# STM32C551xx register map
File version: 1.0
Registers are 32-bit, read-write, reset 0x0 unless marked. A register's access mark holds for its fields unless they carry their own. Offsets are from the block's base; [hi:lo] are bit positions.

## SPI2 — Serial peripheral interface (SPI)
Base 0x40003800
Same registers: SPI3 0x40003C00, SPI1 0x40013000
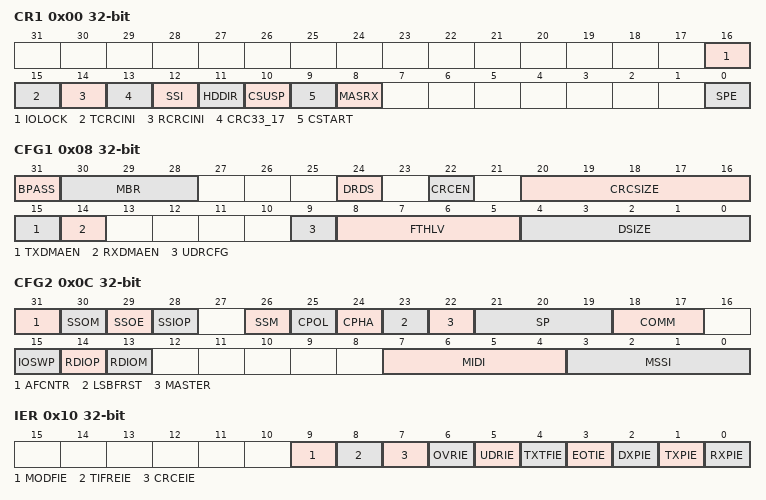
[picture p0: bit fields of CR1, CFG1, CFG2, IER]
0x00 CR1 — SPI/I2S Control register 1
  [16] IOLOCK — Locking the AF configuration of associated IOs
  [15] TCRCINI — CRC init pattern control for transmitter
  [14] RCRCINI — CRC init pattern control for receiver
  [13] CRC33_17 — 32-bit CRC polynomial configuration
  [12] SSI — Internal SS signal input level
  [11] HDDIR — Rx/Tx direction at Half-duplex mode
  [10] CSUSP — Master SUSPend request
  [9] CSTART — Master transfer start
  [8] MASRX — Master automatic SUSP in Receive mode
  [0] SPE — Serial Peripheral Enable
0x04 CR2 — SPI Control register 2
  [15:0] TSIZE — Number of data at current transfer
0x08 CFG1 — SPI Configuration register 1
  [31] BPASS — Bypass of the prescaler
  [30:28] MBR — Master baud rate
  [24] DRDS — Delay Read Data Sampling
  [22] CRCEN — Hardware CRC computation enable
  [20:16] CRCSIZE — CRCSIZE [4:0]: Length of CRC frame
  [15] TXDMAEN — Tx DMA stream enable
  [14] RXDMAEN — Rx DMA stream enable
  [9] UDRCFG — Behavior of Slave transmitter at underrun
  [8:5] FTHLV — FTHVL [3:0]: FIFO threshold level
  [4:0] DSIZE — DSIZE[4:0]: Bits number in single SPI data frame
0x0C CFG2 — SPI Configuration register 2
  [31] AFCNTR — Alternate function GPIOs control
  [30] SSOM — SS output management in master mode
  [29] SSOE — SS output enable
  [28] SSIOP — SS input/output polarity
  [26] SSM — Software slave management
  [25] CPOL — Clock Polarity
  [24] CPHA — Clock Phase
  [23] LSBFRST — Data frame format
  [22] MASTER — SPI Master
  [21:19] SP — SP[2:0]: Serial Protocol
  [18:17] COMM — COMM [1:0]: SPI Communication Mode
  [15] IOSWP — Swap functionality of MISO and MOSI pins
  [14] RDIOP — RDY signal input/output polarity
  [13] RDIOM — RDY signal input/output management
  [7:4] MIDI — Master Inter-Data Idleness
  [3:0] MSSI — Master SS Idleness
0x10 IER — SPI Interrupt Enable register
  [9] MODFIE — MODF interrupt enable
  [8] TIFREIE — TI Frame Error interrupt enable
  [7] CRCEIE — CRCE interrupt enable
  [6] OVRIE — OVR interrupt enable
  [5] UDRIE — UDR interrupt enable
  [4] TXTFIE — TXTF interrupt enable
  [3] EOTIE — EOT/SUSP/TXC interrupt enable
  [2] DXPIE — DXP interrupt enable
  [1] TXPIE — TXP interrupt enable
  [0] RXPIE — RXP Interrupt Enable
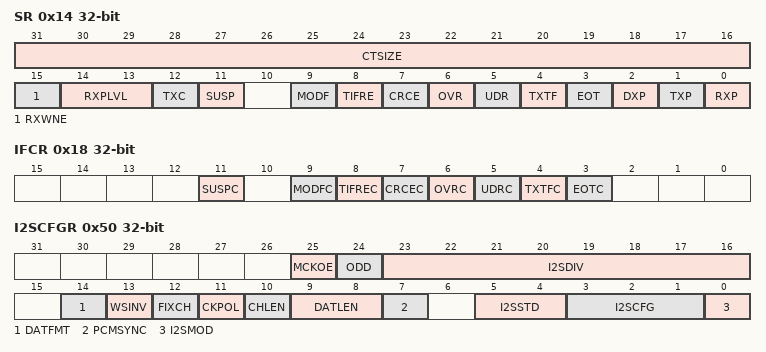
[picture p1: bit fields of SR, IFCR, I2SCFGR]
0x14 SR ro — SPI Status register
  [31:16] CTSIZE — Number of data frames remaining in TSIZE
  [15] RXWNE — Rx FIFO Word Not Empty
  [14:13] RXPLVL — RxFIFO Packing Level
  [12] TXC — TxFIFO transmission complete
  [11] SUSP — SUSP is set by hardware
  [9] MODF — Mode Fault Detected
  [8] TIFRE — TI frame format error Detected
  [7] CRCE — CRC Error Detected
  [6] OVR — Rx-Packet available
  [5] UDR — UDR at Slave transmission
  [4] TXTF — Transmission Transfer Filled
  [3] EOT — Duplex Packet available
  [2] DXP — Duplex Packet available
  [1] TXP — Tx-Packet space available
  [0] RXP — Rx-Packet available
0x18 IFCR — SPI Interrupt/Status Flags Clear register
  [11] SUSPC — SUSPend flag clear
  [9] MODFC — Mode Fault flag clear
  [8] TIFREC — TI frame format error flag clear
  [7] CRCEC — CRC Error flag clear
  [6] OVRC — Overrun flag clear
  [5] UDRC — Underrun flag clear
  [4] TXTFC — Transmission Transfer Filled flag clear
  [3] EOTC — End Of Transfer flag clear
0x1C AUTOCR — SPI Autonomous Mode Control register
0x20 TXDR — SPI Transmit data register
0x30 RXDR ro — SPI/I2S data register
0x40 CRCPOLY — SPI CRC Polynomial register
0x44 TXCRC ro — SPI Transmitter CRC register
0x48 RXCRC ro — SPI Receiver CRC register
0x4C UDRDR — SPI Underrun data register
0x50 I2SCFGR — I2S Configuration register
  [25] MCKOE — Master Clock Output Enable
  [24] ODD — Odd factor for the prescaler
  [23:16] I2SDIV — I2S Linear prescaler
  [14] DATFMT — Data format
  [13] WSINV — Word select inversion
  [12] FIXCH — Fixed channel length in SLAVE
  [11] CKPOL — Steady state clock polarity
  [10] CHLEN — Channel length (number of bits per audio channel)
  [9:8] DATLEN — DATLEN[1:0] Data length to be transferred
  [7] PCMSYNC — PCM frame synchronization
  [5:4] I2SSTD — I2SSTD[1:0] I2S standard selection
  [3:1] I2SCFG — I2SCFG[2:0] I2S configuration mode
  [0] I2SMOD — I2S mode selection
